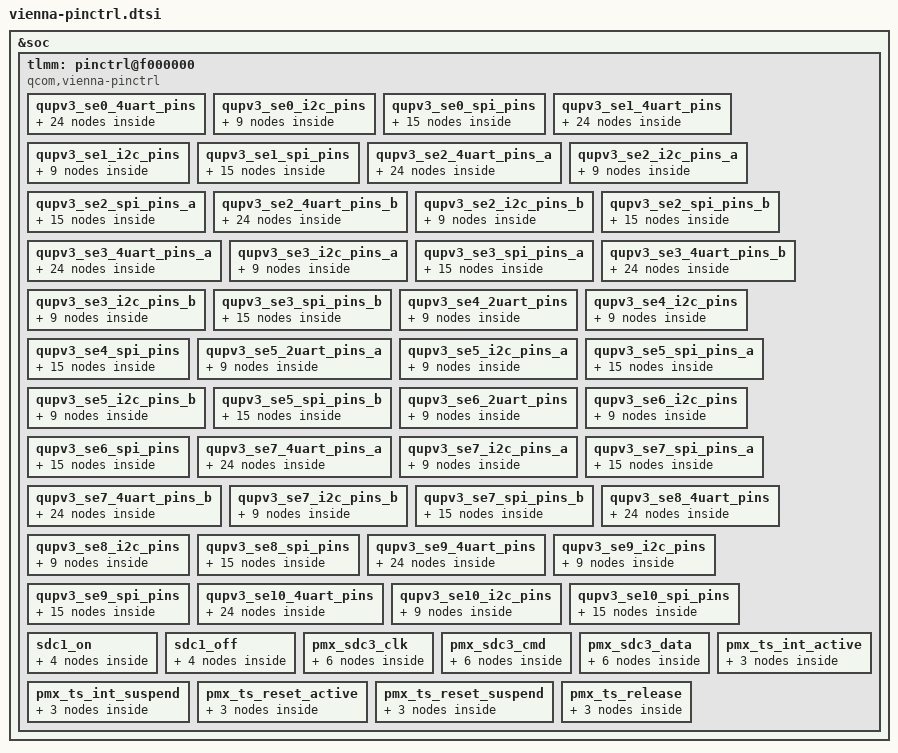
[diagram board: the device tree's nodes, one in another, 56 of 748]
// SPDX-License-Identifier: BSD-3-Clause
/*
 *Copyright (c) Qualcomm Technologies, Inc. and/or its subsidiaries.
 */

&soc {

	tlmm: pinctrl@f000000 {
		compatible = "qcom,vienna-pinctrl";
		reg = <0x0F000000 0x1000000>;
		interrupts = <GIC_SPI 208 IRQ_TYPE_LEVEL_HIGH>;
		gpio-controller;
		#gpio-cells = <2>;
		interrupt-controller;
		#interrupt-cells = <2>;
		wakeup-parent = <&pdc>;
		qcom,gpios-reserved = <0 1 2 3 14 15 73 74 88>;

		qupv3_se0_4uart_pins: qupv3_se0_4uart_pins {
			qupv3_se0_default_cts: qupv3_se0_default_cts {
				mux {
					pins = "gpio0";
					function = "gpio";
				};

				config {
					pins = "gpio0";
					drive-strength = <2>;
					bias-disable;
				};
			};

			qupv3_se0_default_rts: qupv3_se0_default_rts {
				mux {
					pins = "gpio1";
					function = "gpio";
				};

				config {
					pins = "gpio1";
					drive-strength = <2>;
					bias-pull-down;
				};
			};

			qupv3_se0_default_tx: qupv3_se0_default_tx {
				mux {
					pins = "gpio2";
					function = "gpio";
				};

				config {
					pins = "gpio2";
					drive-strength = <2>;
					bias-pull-up;
				};
			};

			qupv3_se0_default_rx: qupv3_se0_default_rx {
				mux {
					pins = "gpio3";
					function = "gpio";
				};

				config {
					pins = "gpio3";
					drive-strength = <2>;
					bias-pull-down;
				};
			};

			qupv3_se0_cts: qupv3_se0_cts {
				mux {
					pins = "gpio0";
					function = "qup0_se0_l0";
				};

				config {
					pins = "gpio0";
					drive-strength = <2>;
					bias-disable;
				};
			};

			qupv3_se0_rts: qupv3_se0_rts {
				mux {
					pins = "gpio1";
					function = "qup0_se0_l1";
				};

				config {
					pins = "gpio1";
					drive-strength = <2>;
					bias-pull-down;
				};
			};

			qupv3_se0_tx: qupv3_se0_tx {
				mux {
					pins = "gpio2";
					function = "qup0_se0_l2";
				};

				config {
					pins = "gpio2";
					drive-strength = <2>;
					bias-pull-up;
				};
			};

			qupv3_se0_rx_active: qupv3_se0_rx_active {
				mux {
					pins = "gpio3";
					function = "qup0_se0_l3";
				};

				config {
					pins = "gpio3";
					drive-strength = <2>;
					bias-disable;
				};
			};
		};

		qupv3_se0_i2c_pins: qupv3_se0_i2c_pins {
			qupv3_se0_i2c_sda_active: qupv3_se0_i2c_sda_active {
				mux {
					pins = "gpio0";
					function = "qup0_se0_l0";
				};

				config {
					pins = "gpio0";
					drive-strength = <2>;
					bias-pull-up;
					qcom,i2c_pull;
				};
			};

			qupv3_se0_i2c_scl_active: qupv3_se0_i2c_scl_active {
				mux {
					pins = "gpio1";
					function = "qup0_se0_l1";
				};

				config {
					pins = "gpio1";
					drive-strength = <2>;
					bias-pull-up;
					qcom,i2c_pull;
				};
			};

			qupv3_se0_i2c_sleep: qupv3_se0_i2c_sleep {
				mux {
					pins = "gpio0", "gpio1";
					function = "gpio";
				};

				config {
					pins = "gpio0", "gpio1";
					drive-strength = <2>;
				};
			};
		};

		qupv3_se0_spi_pins: qupv3_se0_spi_pins {
			qupv3_se0_spi_miso_active: qupv3_se0_spi_miso_active {
				mux {
					pins = "gpio0";
					function = "qup0_se0_l0";
				};

				config {
					pins = "gpio0";
					drive-strength = <6>;
					bias-disable;
				};
			};

			qupv3_se0_spi_mosi_active: qupv3_se0_spi_mosi_active {
				mux {
					pins = "gpio1";
					function = "qup0_se0_l1";
				};

				config {
					pins = "gpio1";
					drive-strength = <6>;
					bias-disable;
				};
			};

			qupv3_se0_spi_clk_active: qupv3_se0_spi_clk_active {
				mux {
					pins = "gpio2";
					function = "qup0_se0_l2";
				};

				config {
					pins = "gpio2";
					drive-strength = <6>;
					bias-disable;
				};
			};

			qupv3_se0_spi_cs_active: qupv3_se0_spi_cs_active {
				mux {
					pins = "gpio3";
					function = "qup0_se0_l3";
				};

				config {
					pins = "gpio3";
					drive-strength = <6>;
					bias-disable;
				};
			};

			qupv3_se0_spi_sleep: qupv3_se0_spi_sleep {
				mux {
					pins = "gpio0", "gpio1",
						"gpio2", "gpio3";
					function = "gpio";
				};

				config {
					pins = "gpio0", "gpio1",
						"gpio2", "gpio3";
					drive-strength = <2>;
					bias-disable;
				};
			};
		};

		qupv3_se1_4uart_pins: qupv3_se1_4uart_pins {
			qupv3_se1_default_cts: qupv3_se1_default_cts {
				mux {
					pins = "gpio4";
					function = "gpio";
				};

				config {
					pins = "gpio4";
					drive-strength = <2>;
					bias-disable;
				};
			};

			qupv3_se1_default_rts: qupv3_se1_default_rts {
				mux {
					pins = "gpio5";
					function = "gpio";
				};

				config {
					pins = "gpio5";
					drive-strength = <2>;
					bias-pull-down;
				};
			};

			qupv3_se1_default_tx: qupv3_se1_default_tx {
				mux {
					pins = "gpio7";
					function = "gpio";
				};

				config {
					pins = "gpio7";
					drive-strength = <2>;
					bias-pull-up;
				};
			};

			qupv3_se1_default_rx: qupv3_se1_default_rx {
				mux {
					pins = "gpio24";
					function = "gpio";
				};

				config {
					pins = "gpio24";
					drive-strength = <2>;
					bias-pull-down;
				};
			};

			qupv3_se1_cts: qupv3_se1_cts {
				mux {
					pins = "gpio4";
					function = "qup0_se1_l0";
				};

				config {
					pins = "gpio4";
					drive-strength = <2>;
					bias-disable;
				};
			};

			qupv3_se1_rts: qupv3_se1_rts {
				mux {
					pins = "gpio5";
					function = "qup0_se1_l1";
				};

				config {
					pins = "gpio5";
					drive-strength = <2>;
					bias-pull-down;
				};
			};

			qupv3_se1_tx: qupv3_se1_tx {
				mux {
					pins = "gpio7";
					function = "qup0_se1_l2";
				};

				config {
					pins = "gpio7";
					drive-strength = <2>;
					bias-pull-up;
				};
			};

			qupv3_se1_rx_active: qupv3_se1_rx_active {
				mux {
					pins = "gpio24";
					function = "qup0_se1_l3";
				};

				config {
					pins = "gpio24";
					drive-strength = <2>;
					bias-disable;
				};
			};
		};

		qupv3_se1_i2c_pins: qupv3_se1_i2c_pins {
			qupv3_se1_i2c_sda_active: qupv3_se1_i2c_sda_active {
				mux {
					pins = "gpio4";
					function = "qup0_se1_l0";
				};

				config {
					pins = "gpio4";
					drive-strength = <2>;
					bias-pull-up;
					qcom,i2c_pull;
				};
			};

			qupv3_se1_i2c_scl_active: qupv3_se1_i2c_scl_active {
				mux {
					pins = "gpio5";
					function = "qup0_se1_l1";
				};

				config {
					pins = "gpio5";
					drive-strength = <2>;
					bias-pull-up;
					qcom,i2c_pull;
				};
			};

			qupv3_se1_i2c_sleep: qupv3_se1_i2c_sleep {
				mux {
					pins = "gpio4", "gpio5";
					function = "gpio";
				};

				config {
					pins = "gpio4", "gpio5";
					drive-strength = <2>;
				};
			};
		};

		qupv3_se1_spi_pins: qupv3_se1_spi_pins {
			qupv3_se1_spi_miso_active: qupv3_se1_spi_miso_active {
				mux {
					pins = "gpio4";
					function = "qup0_se1_l0";
				};

				config {
					pins = "gpio4";
					drive-strength = <6>;
					bias-disable;
				};
			};

			qupv3_se1_spi_mosi_active: qupv3_se1_spi_mosi_active {
				mux {
					pins = "gpio5";
					function = "qup0_se1_l1";
				};

				config {
					pins = "gpio5";
					drive-strength = <6>;
					bias-disable;
				};
			};

			qupv3_se1_spi_clk_active: qupv3_se1_spi_clk_active {
				mux {
					pins = "gpio7";
					function = "qup0_se1_l2";
				};

				config {
					pins = "gpio7";
					drive-strength = <6>;
					bias-disable;
				};
			};

			qupv3_se1_spi_cs_active: qupv3_se1_spi_cs_active {
				mux {
					pins = "gpio24";
					function = "qup0_se1_l3";
				};

				config {
					pins = "gpio24";
					drive-strength = <6>;
					bias-disable;
				};
			};

			qupv3_se1_spi_sleep: qupv3_se1_spi_sleep {
				mux {
					pins = "gpio4", "gpio5",
						"gpio7", "gpio24";
					function = "gpio";
				};

				config {
					pins = "gpio4", "gpio5",
						"gpio7", "gpio24";
					drive-strength = <2>;
					bias-disable;
				};
			};
		};

		qupv3_se2_4uart_pins_a: qupv3_se2_4uart_pins_a {
			qupv3_se2_default_cts_a: qupv3_se2_default_cts_a {
				mux {
					pins = "gpio8";
					function = "gpio";
				};

				config {
					pins = "gpio8";
					drive-strength = <2>;
					bias-disable;
				};
			};

			qupv3_se2_default_rts_a: qupv3_se2_default_rts_a {
				mux {
					pins = "gpio9";
					function = "gpio";
				};

				config {
					pins = "gpio9";
					drive-strength = <2>;
					bias-pull-down;
				};
			};

			qupv3_se2_default_tx_a: qupv3_se2_default_tx_a {
				mux {
					pins = "gpio10";
					function = "gpio";
				};

				config {
					pins = "gpio10";
					drive-strength = <2>;
					bias-pull-up;
				};
			};

			qupv3_se2_default_rx_a: qupv3_se2_default_rx_a {
				mux {
					pins = "gpio11";
					function = "gpio";
				};

				config {
					pins = "gpio11";
					drive-strength = <2>;
					bias-pull-down;
				};
			};

			qupv3_se2_cts_a: qupv3_se2_cts_a {
				mux {
					pins = "gpio8";
					function = "qup0_se2_l0_mira";
				};

				config {
					pins = "gpio8";
					drive-strength = <2>;
					bias-disable;
				};
			};

			qupv3_se2_rts_a: qupv3_se2_rts_a {
				mux {
					pins = "gpio9";
					function = "qup0_se2_l1_mira";
				};

				config {
					pins = "gpio9";
					drive-strength = <2>;
					bias-pull-down;
				};
			};

			qupv3_se2_tx_a: qupv3_se2_tx_a {
				mux {
					pins = "gpio10";
					function = "qup0_se2_l2_mira";
				};

				config {
					pins = "gpio10";
					drive-strength = <2>;
					bias-pull-up;
				};
			};

			qupv3_se2_rx_active_a: qupv3_se2_rx_active_a {
				mux {
					pins = "gpio11";
					function = "qup0_se2_l3_mira";
				};

				config {
					pins = "gpio11";
					drive-strength = <2>;
					bias-disable;
				};
			};
		};

		qupv3_se2_i2c_pins_a: qupv3_se2_i2c_pins_a {
			qupv3_se2_i2c_sda_active_a: qupv3_se2_i2c_sda_active_a {
				mux {
					pins = "gpio8";
					function = "qup0_se2_l0_mira";
				};

				config {
					pins = "gpio8";
					drive-strength = <2>;
					bias-pull-up;
					qcom,i2c_pull;
				};
			};

			qupv3_se2_i2c_scl_active_a: qupv3_se2_i2c_scl_active_a {
				mux {
					pins = "gpio9";
					function = "qup0_se2_l1_mira";
				};

				config {
					pins = "gpio9";
					drive-strength = <2>;
					bias-pull-up;
					qcom,i2c_pull;
				};
			};

			qupv3_se2_i2c_sleep_a: qupv3_se2_i2c_sleep_a {
				mux {
					pins = "gpio8", "gpio9";
					function = "gpio";
				};

				config {
					pins = "gpio8", "gpio9";
					drive-strength = <2>;
				};
			};
		};

		qupv3_se2_spi_pins_a: qupv3_se2_spi_pins_a {
			qupv3_se2_spi_miso_active_a: qupv3_se2_spi_miso_active_a {
				mux {
					pins = "gpio8";
					function = "qup0_se2_l0_mira";
				};

				config {
					pins = "gpio8";
					drive-strength = <6>;
					bias-disable;
				};
			};

			qupv3_se2_spi_mosi_active_a: qupv3_se2_spi_mosi_active_a {
				mux {
					pins = "gpio9";
					function = "qup0_se2_l1_mira";
				};

				config {
					pins = "gpio9";
					drive-strength = <6>;
					bias-disable;
				};
			};

			qupv3_se2_spi_clk_active_a: qupv3_se2_spi_clk_active_a {
				mux {
					pins = "gpio10";
					function = "qup0_se2_l2_mira";
				};

				config {
					pins = "gpio10";
					drive-strength = <6>;
					bias-disable;
				};
			};

			qupv3_se2_spi_cs_active_a: qupv3_se2_spi_cs_active_a {
				mux {
					pins = "gpio11";
					function = "qup0_se2_l3_mira";
				};

				config {
					pins = "gpio11";
					drive-strength = <6>;
					bias-disable;
				};
			};

			qupv3_se2_spi_sleep_a: qupv3_se2_spi_sleep_a {
				mux {
					pins = "gpio8", "gpio9",
						"gpio10", "gpio11";
					function = "gpio";
				};

				config {
					pins = "gpio8", "gpio9",
						"gpio10", "gpio11";
					drive-strength = <2>;
					bias-disable;
				};
			};
		};

		qupv3_se2_4uart_pins_b: qupv3_se2_4uart_pins_b {
			qupv3_se2_default_cts_b: qupv3_se2_default_cts_b {
				mux {
					pins = "gpio134";
					function = "gpio";
				};

				config {
					pins = "gpio134";
					drive-strength = <2>;
					bias-disable;
				};
			};

			qupv3_se2_default_rts_b: qupv3_se2_default_rts_b {
				mux {
					pins = "gpio133";
					function = "gpio";
				};

				config {
					pins = "gpio133";
					drive-strength = <2>;
					bias-pull-down;
				};
			};

			qupv3_se2_default_tx_b: qupv3_se2_default_tx_b {
				mux {
					pins = "gpio132";
					function = "gpio";
				};

				config {
					pins = "gpio132";
					drive-strength = <2>;
					bias-pull-up;
				};
			};

			qupv3_se2_default_rx_b: qupv3_se2_default_rx_b {
				mux {
					pins = "gpio131";
					function = "gpio";
				};

				config {
					pins = "gpio131";
					drive-strength = <2>;
					bias-pull-down;
				};
			};

			qupv3_se2_cts_b: qupv3_se2_cts_b {
				mux {
					pins = "gpio134";
					function = "qup0_se2_l0_mirb";
				};

				config {
					pins = "gpio134";
					drive-strength = <2>;
					bias-disable;
				};
			};

			qupv3_se2_rts_b: qupv3_se2_rts_b {
				mux {
					pins = "gpio133";
					function = "qup0_se2_l1_mirb";
				};

				config {
					pins = "gpio133";
					drive-strength = <2>;
					bias-pull-down;
				};
			};

			qupv3_se2_tx_b: qupv3_se2_tx_b {
				mux {
					pins = "gpio132";
					function = "qup0_se2_l2_mirb";
				};

				config {
					pins = "gpio132";
					drive-strength = <2>;
					bias-pull-up;
				};
			};

			qupv3_se2_rx_active_b: qupv3_se2_rx_active_b {
				mux {
					pins = "gpio131";
					function = "qup0_se2_l3_mirb";
				};

				config {
					pins = "gpio131";
					drive-strength = <2>;
					bias-disable;
				};
			};
		};

		qupv3_se2_i2c_pins_b: qupv3_se2_i2c_pins_b {
			qupv3_se2_i2c_sda_active_b: qupv3_se2_i2c_sda_active_b {
				mux {
					pins = "gpio134";
					function = "qup0_se2_l0_mirb";
				};

				config {
					pins = "gpio134";
					drive-strength = <2>;
					bias-pull-up;
					qcom,i2c_pull;
				};
			};

			qupv3_se2_i2c_scl_active_b: qupv3_se2_i2c_scl_active_b {
				mux {
					pins = "gpio133";
					function = "qup0_se2_l1_mirb";
				};

				config {
					pins = "gpio133";
					drive-strength = <2>;
					bias-pull-up;
					qcom,i2c_pull;
				};
			};

			qupv3_se2_i2c_sleep_b: qupv3_se2_i2c_sleep_b {
				mux {
					pins = "gpio134", "gpio133";
					function = "gpio";
				};

				config {
					pins = "gpio134", "gpio133";
					drive-strength = <2>;
				};
			};
		};

		qupv3_se2_spi_pins_b: qupv3_se2_spi_pins_b {
			qupv3_se2_spi_miso_active_b: qupv3_se2_spi_miso_active_b {
				mux {
					pins = "gpio134";
					function = "qup0_se2_l0_mirb";
				};

				config {
					pins = "gpio134";
					drive-strength = <6>;
					bias-disable;
				};
			};

			qupv3_se2_spi_mosi_active_b: qupv3_se2_spi_mosi_active_b {
				mux {
					pins = "gpio133";
					function = "qup0_se2_l1_mirb";
				};

				config {
					pins = "gpio133";
					drive-strength = <6>;
					bias-disable;
				};
			};

			qupv3_se2_spi_clk_active_b: qupv3_se2_spi_clk_active_b {
				mux {
					pins = "gpio132";
					function = "qup0_se2_l2_mirb";
				};

				config {
					pins = "gpio132";
					drive-strength = <6>;
					bias-disable;
				};
			};

			qupv3_se2_spi_cs_active_b: qupv3_se2_spi_cs_active_b {
				mux {
					pins = "gpio131";
					function = "qup0_se2_l3_mirb";
				};

				config {
					pins = "gpio131";
					drive-strength = <6>;
					bias-disable;
				};
			};

			qupv3_se2_spi_sleep_b: qupv3_se2_spi_sleep_b {
				mux {
					pins = "gpio134", "gpio133",
						"gpio132", "gpio131";
					function = "gpio";
				};

				config {
					pins = "gpio134", "gpio133",
						"gpio132", "gpio131";
					drive-strength = <2>;
					bias-disable;
				};
			};
		};

		qupv3_se3_4uart_pins_a: qupv3_se3_4uart_pins_a {
			qupv3_se3_default_cts_a: qupv3_se3_default_cts_a {
				mux {
					pins = "gpio8";
					function = "gpio";
				};

				config {
					pins = "gpio8";
					drive-strength = <2>;
					bias-disable;
				};
			};

			qupv3_se3_default_rts_a: qupv3_se3_default_rts_a {
				mux {
					pins = "gpio9";
					function = "gpio";
				};

				config {
					pins = "gpio9";
					drive-strength = <2>;
					bias-pull-down;
				};
			};

			qupv3_se3_default_tx_a: qupv3_se3_default_tx_a {
				mux {
					pins = "gpio10";
					function = "gpio";
				};

				config {
					pins = "gpio10";
					drive-strength = <2>;
					bias-pull-up;
				};
			};

			qupv3_se3_default_rx_a: qupv3_se3_default_rx_a {
				mux {
					pins = "gpio11";
					function = "gpio";
				};

				config {
					pins = "gpio11";
					drive-strength = <2>;
					bias-pull-down;
				};
			};

			qupv3_se3_cts_a: qupv3_se3_cts_a {
				mux {
					pins = "gpio8";
					function = "qup0_se3_l0_mirb";
				};

				config {
					pins = "gpio8";
					drive-strength = <2>;
					bias-disable;
				};
			};

			qupv3_se3_rts_a: qupv3_se3_rts_a {
				mux {
					pins = "gpio9";
					function = "qup0_se3_l1_mirb";
				};

				config {
					pins = "gpio9";
					drive-strength = <2>;
					bias-pull-down;
				};
			};

			qupv3_se3_tx_a: qupv3_se3_tx_a {
				mux {
					pins = "gpio10";
					function = "qup0_se3_l2_mirb";
				};

				config {
					pins = "gpio10";
					drive-strength = <2>;
					bias-pull-up;
				};
			};

			qupv3_se3_rx_active_a: qupv3_se3_rx_active_a {
				mux {
					pins = "gpio11";
					function = "qup0_se3_l3_mirb";
				};

				config {
					pins = "gpio11";
					drive-strength = <2>;
					bias-disable;
				};
			};
		};

		qupv3_se3_i2c_pins_a: qupv3_se3_i2c_pins_a {
			qupv3_se3_i2c_sda_active_a: qupv3_se3_i2c_sda_active_a {
				mux {
					pins = "gpio8";
					function = "qup0_se3_l0_mirb";
				};

				config {
					pins = "gpio8";
					drive-strength = <2>;
					bias-pull-up;
					qcom,i2c_pull;
				};
			};

			qupv3_se3_i2c_scl_active_a: qupv3_se3_i2c_scl_active_a {
				mux {
					pins = "gpio9";
					function = "qup0_se3_l1_mirb";
				};

				config {
					pins = "gpio9";
					drive-strength = <2>;
					bias-pull-up;
					qcom,i2c_pull;
				};
			};

			qupv3_se3_i2c_sleep_a: qupv3_se3_i2c_sleep_a {
				mux {
					pins = "gpio8", "gpio9";
					function = "gpio";
				};

				config {
					pins = "gpio8", "gpio9";
					drive-strength = <2>;
				};
			};
		};

		qupv3_se3_spi_pins_a: qupv3_se3_spi_pins_a {
			qupv3_se3_spi_miso_active_a: qupv3_se3_spi_miso_active_a {
				mux {
					pins = "gpio8";
					function = "qup0_se3_l0_mirb";
				};

				config {
					pins = "gpio8";
					drive-strength = <6>;
					bias-disable;
				};
			};

			qupv3_se3_spi_mosi_active_a: qupv3_se3_spi_mosi_active_a {
				mux {
					pins = "gpio9";
					function = "qup0_se3_l1_mirb";
				};

				config {
					pins = "gpio9";
					drive-strength = <6>;
					bias-disable;
				};
			};

			qupv3_se3_spi_clk_active_a: qupv3_se3_spi_clk_active_a {
				mux {
					pins = "gpio10";
					function = "qup0_se3_l2_mirb";
				};

				config {
					pins = "gpio10";
					drive-strength = <6>;
					bias-disable;
				};
			};

			qupv3_se3_spi_cs_active_a: qupv3_se3_spi_cs_active_a {
				mux {
					pins = "gpio11";
					function = "qup0_se3_l3_mirb";
				};

				config {
					pins = "gpio11";
					drive-strength = <6>;
					bias-disable;
				};
			};

			qupv3_se3_spi_sleep_a: qupv3_se3_spi_sleep_a {
				mux {
					pins = "gpio8", "gpio9",
						"gpio10", "gpio11";
					function = "gpio";
				};

				config {
					pins = "gpio8", "gpio9",
						"gpio10", "gpio11";
					drive-strength = <2>;
					bias-disable;
				};
			};
		};

		qupv3_se3_4uart_pins_b: qupv3_se3_4uart_pins_b {
			qupv3_se3_default_cts_b: qupv3_se3_default_cts_b {
				mux {
					pins = "gpio111";
					function = "gpio";
				};

				config {
					pins = "gpio111";
					drive-strength = <2>;
					bias-disable;
				};
			};

			qupv3_se3_default_rts_b: qupv3_se3_default_rts_b {
				mux {
					pins = "gpio112";
					function = "gpio";
				};

				config {
					pins = "gpio112";
					drive-strength = <2>;
					bias-pull-down;
				};
			};

			qupv3_se3_default_tx_b: qupv3_se3_default_tx_b {
				mux {
					pins = "gpio14";
					function = "gpio";
				};

				config {
					pins = "gpio14";
					drive-strength = <2>;
					bias-pull-up;
				};
			};

			qupv3_se3_default_rx_b: qupv3_se3_default_rx_b {
				mux {
					pins = "gpio15";
					function = "gpio";
				};

				config {
					pins = "gpio15";
					drive-strength = <2>;
					bias-pull-down;
				};
			};

			qupv3_se3_cts_b: qupv3_se3_cts_b {
				mux {
					pins = "gpio111";
					function = "qup0_se3_l0_mira";
				};

				config {
					pins = "gpio111";
					drive-strength = <2>;
					bias-disable;
				};
			};

			qupv3_se3_rts_b: qupv3_se3_rts_b {
				mux {
					pins = "gpio112";
					function = "qup0_se3_l1_mira";
				};

				config {
					pins = "gpio112";
					drive-strength = <2>;
					bias-pull-down;
				};
			};

			qupv3_se3_tx_b: qupv3_se3_tx_b {
				mux {
					pins = "gpio14";
					function = "qup0_se3_l2_mira";
				};

				config {
					pins = "gpio14";
					drive-strength = <2>;
					bias-pull-up;
				};
			};

			qupv3_se3_rx_active_b: qupv3_se3_rx_active_b {
				mux {
					pins = "gpio15";
					function = "qup0_se3_l3_mira";
				};

				config {
					pins = "gpio15";
					drive-strength = <2>;
					bias-disable;
				};
			};
		};

		qupv3_se3_i2c_pins_b: qupv3_se3_i2c_pins_b {
			qupv3_se3_i2c_sda_active_b: qupv3_se3_i2c_sda_active_b {
				mux {
					pins = "gpio111";
					function = "qup0_se3_l0_mira";
				};

				config {
					pins = "gpio111";
					drive-strength = <2>;
					bias-pull-up;
					qcom,i2c_pull;
				};
			};

			qupv3_se3_i2c_scl_active_b: qupv3_se3_i2c_scl_active_b {
				mux {
					pins = "gpio112";
					function = "qup0_se3_l1_mira";
				};

				config {
					pins = "gpio112";
					drive-strength = <2>;
					bias-pull-up;
					qcom,i2c_pull;
				};
			};

			qupv3_se3_i2c_sleep_b: qupv3_se3_i2c_sleep_b {
				mux {
					pins = "gpio111", "gpio112";
					function = "gpio";
				};

				config {
					pins = "gpio111", "gpio112";
					drive-strength = <2>;
				};
			};
		};

		qupv3_se3_spi_pins_b: qupv3_se3_spi_pins_b {
			qupv3_se3_spi_miso_active_b: qupv3_se3_spi_miso_active_b {
				mux {
					pins = "gpio111";
					function = "qup0_se3_l0_mira";
				};

				config {
					pins = "gpio111";
					drive-strength = <6>;
					bias-disable;
				};
			};

			qupv3_se3_spi_mosi_active_b: qupv3_se3_spi_mosi_active_b {
				mux {
					pins = "gpio112";
					function = "qup0_se3_l1_mira";
				};

				config {
					pins = "gpio112";
					drive-strength = <6>;
					bias-disable;
				};
			};

			qupv3_se3_spi_clk_active_b: qupv3_se3_spi_clk_active_b {
				mux {
					pins = "gpio14";
					function = "qup0_se3_l2_mira";
				};

				config {
					pins = "gpio14";
					drive-strength = <6>;
					bias-disable;
				};
			};

			qupv3_se3_spi_cs_active_b: qupv3_se3_spi_cs_active_b {
				mux {
					pins = "gpio15";
					function = "qup0_se3_l3_mira";
				};

				config {
					pins = "gpio15";
					drive-strength = <6>;
					bias-disable;
				};
			};

			qupv3_se3_spi_sleep_b: qupv3_se3_spi_sleep_b {
				mux {
					pins = "gpio111", "gpio112",
						"gpio14", "gpio15";
					function = "gpio";
				};

				config {
					pins = "gpio111", "gpio112",
						"gpio14", "gpio15";
					drive-strength = <2>;
					bias-disable;
				};
			};
		};

		qupv3_se4_2uart_pins: qupv3_se4_2uart_pins {
			qupv3_se4_2uart_tx_active: qupv3_se4_2uart_tx_active {
				mux {
					pins = "gpio18";
					function = "qup0_se4_l2";
				};

				config {
					pins = "gpio18";
					drive-strength = <2>;
					bias-disable;
				};
			};

			qupv3_se4_2uart_rx_active: qupv3_se4_2uart_rx_active {
				mux {
					pins = "gpio19";
					function = "qup0_se4_l3";
				};

				config {
					pins = "gpio19";
					drive-strength = <2>;
					bias-disable;
				};
			};

			qupv3_se4_2uart_sleep: qupv3_se4_2uart_sleep {
				mux {
					pins = "gpio18", "gpio19";
					function = "gpio";
				};

				config {
					pins = "gpio18", "gpio19";
					drive-strength = <2>;
					bias-pull-down;
				};
			};
		};

		qupv3_se4_i2c_pins: qupv3_se4_i2c_pins {
			qupv3_se4_i2c_sda_active: qupv3_se4_i2c_sda_active {
				mux {
					pins = "gpio16";
					function = "qup0_se4_l0";
				};

				config {
					pins = "gpio16";
					drive-strength = <2>;
					bias-pull-up;
					qcom,i2c_pull;
				};
			};

			qupv3_se4_i2c_scl_active: qupv3_se4_i2c_scl_active {
				mux {
					pins = "gpio17";
					function = "qup0_se4_l1";
				};

				config {
					pins = "gpio17";
					drive-strength = <2>;
					bias-pull-up;
					qcom,i2c_pull;
				};
			};

			qupv3_se4_i2c_sleep: qupv3_se4_i2c_sleep {
				mux {
					pins = "gpio16", "gpio17";
					function = "gpio";
				};

				config {
					pins = "gpio16", "gpio17";
					drive-strength = <2>;
				};
			};
		};

		qupv3_se4_spi_pins: qupv3_se4_spi_pins {
			qupv3_se4_spi_miso_active: qupv3_se4_spi_miso_active {
				mux {
					pins = "gpio16";
					function = "qup0_se4_l0";
				};

				config {
					pins = "gpio16";
					drive-strength = <6>;
					bias-disable;
				};
			};

			qupv3_se4_spi_mosi_active: qupv3_se4_spi_mosi_active {
				mux {
					pins = "gpio17";
					function = "qup0_se4_l1";
				};

				config {
					pins = "gpio17";
					drive-strength = <6>;
					bias-disable;
				};
			};

			qupv3_se4_spi_clk_active: qupv3_se4_spi_clk_active {
				mux {
					pins = "gpio18";
					function = "qup0_se4_l2";
				};

				config {
					pins = "gpio18";
					drive-strength = <6>;
					bias-disable;
				};
			};

			qupv3_se4_spi_cs_active: qupv3_se4_spi_cs_active {
				mux {
					pins = "gpio19";
					function = "qup0_se4_l3";
				};

				config {
					pins = "gpio19";
					drive-strength = <6>;
					bias-disable;
				};
			};

			qupv3_se4_spi_sleep: qupv3_se4_spi_sleep {
				mux {
					pins = "gpio16", "gpio17",
						"gpio18", "gpio19";
					function = "gpio";
				};

				config {
					pins = "gpio16", "gpio17",
						"gpio18", "gpio19";
					drive-strength = <2>;
					bias-disable;
				};
			};
		};

		qupv3_se5_2uart_pins_a: qupv3_se5_2uart_pins_a {
			qupv3_se5_2uart_tx_active_a: qupv3_se5_2uart_tx_active_a {
				mux {
					pins = "gpio21";
					function = "qup0_se5_l2_mira";
				};

				config {
					pins = "gpio21";
					drive-strength = <2>;
					bias-disable;
				};
			};

			qupv3_se5_2uart_rx_active_a: qupv3_se5_2uart_rx_active_a {
				mux {
					pins = "gpio20";
					function = "qup0_se5_l3_mira";
				};

				config {
					pins = "gpio20";
					drive-strength = <2>;
					bias-disable;
				};
			};

			qupv3_se5_2uart_sleep_a: qupv3_se5_2uart_sleep_a {
				mux {
					pins = "gpio21", "gpio20";
					function = "gpio";
				};

				config {
					pins = "gpio21", "gpio20";
					drive-strength = <2>;
					bias-pull-down;
				};
			};
		};

		qupv3_se5_i2c_pins_a: qupv3_se5_i2c_pins_a {
			qupv3_se5_i2c_sda_active_a: qupv3_se5_i2c_sda_active_a {
				mux {
					pins = "gpio23";
					function = "qup0_se5_l0_mira";
				};

				config {
					pins = "gpio23";
					drive-strength = <2>;
					bias-pull-up;
					qcom,i2c_pull;
				};
			};

			qupv3_se5_i2c_scl_active_a: qupv3_se5_i2c_scl_active_a {
				mux {
					pins = "gpio22";
					function = "qup0_se5_l1_mira";
				};

				config {
					pins = "gpio22";
					drive-strength = <2>;
					bias-pull-up;
					qcom,i2c_pull;
				};
			};

			qupv3_se5_i2c_sleep_a: qupv3_se5_i2c_sleep_a {
				mux {
					pins = "gpio23", "gpio22";
					function = "gpio";
				};

				config {
					pins = "gpio23", "gpio22";
					drive-strength = <2>;
				};
			};
		};

		qupv3_se5_spi_pins_a: qupv3_se5_spi_pins_a {
			qupv3_se5_spi_miso_active_a: qupv3_se5_spi_miso_active_a {
				mux {
					pins = "gpio23";
					function = "qup0_se5_l0_mira";
				};

				config {
					pins = "gpio23";
					drive-strength = <6>;
					bias-disable;
				};
			};

			qupv3_se5_spi_mosi_active_a: qupv3_se5_spi_mosi_active_a {
				mux {
					pins = "gpio22";
					function = "qup0_se5_l1_mira";
				};

				config {
					pins = "gpio22";
					drive-strength = <6>;
					bias-disable;
				};
			};

			qupv3_se5_spi_clk_active_a: qupv3_se5_spi_clk_active_a {
				mux {
					pins = "gpio21";
					function = "qup0_se5_l2_mira";
				};

				config {
					pins = "gpio21";
					drive-strength = <6>;
					bias-disable;
				};
			};

			qupv3_se5_spi_cs_active_a: qupv3_se5_spi_cs_active_a {
				mux {
					pins = "gpio20";
					function = "qup0_se5_l3_mira";
				};

				config {
					pins = "gpio20";
					drive-strength = <6>;
					bias-disable;
				};
			};

			qupv3_se5_spi_sleep_a: qupv3_se5_spi_sleep_a {
				mux {
					pins = "gpio23", "gpio22",
						"gpio21", "gpio20";
					function = "gpio";
				};

				config {
					pins = "gpio23", "gpio22",
						"gpio21", "gpio20";
					drive-strength = <2>;
					bias-disable;
				};
			};
		};

		qupv3_se5_i2c_pins_b: qupv3_se5_i2c_pins_b {
			qupv3_se5_i2c_sda_active_b: qupv3_se5_i2c_sda_active_b {
				mux {
					pins = "gpio33";
					function = "qup0_se5_l0_mirb";
				};

				config {
					pins = "gpio33";
					drive-strength = <2>;
					bias-pull-up;
					qcom,i2c_pull;
				};
			};

			qupv3_se5_i2c_scl_active_b: qupv3_se5_i2c_scl_active_b {
				mux {
					pins = "gpio35";
					function = "qup0_se5_l1_mirb";
				};

				config {
					pins = "gpio35";
					drive-strength = <2>;
					bias-pull-up;
					qcom,i2c_pull;
				};
			};

			qupv3_se5_i2c_sleep_b: qupv3_se5_i2c_sleep_b {
				mux {
					pins = "gpio33", "gpio35";
					function = "gpio";
				};

				config {
					pins = "gpio33", "gpio35";
					drive-strength = <2>;
				};
			};
		};

		qupv3_se5_spi_pins_b: qupv3_se5_spi_pins_b {
			qupv3_se5_spi_miso_active_b: qupv3_se5_spi_miso_active_b {
				mux {
					pins = "gpio33";
					function = "qup0_se5_l0_mirb";
				};

				config {
					pins = "gpio33";
					drive-strength = <6>;
					bias-disable;
				};
			};

			qupv3_se5_spi_mosi_active_b: qupv3_se5_spi_mosi_active_b {
				mux {
					pins = "gpio35";
					function = "qup0_se5_l1_mirb";
				};

				config {
					pins = "gpio35";
					drive-strength = <6>;
					bias-disable;
				};
			};

			qupv3_se5_spi_clk_active_b: qupv3_se5_spi_clk_active_b {
				mux {
					pins = "gpio39";
					function = "qup0_se5_l2_mirb";
				};

				config {
					pins = "gpio39";
					drive-strength = <6>;
					bias-disable;
				};
			};

			qupv3_se5_spi_cs_active_b: qupv3_se5_spi_cs_active_b {
				mux {
					pins = "gpio38";
					function = "qup0_se5_l3_mirb";
				};

				config {
					pins = "gpio38";
					drive-strength = <6>;
					bias-disable;
				};
			};

			qupv3_se5_spi_sleep_b: qupv3_se5_spi_sleep_b {
				mux {
					pins = "gpio33", "gpio35",
						"gpio39", "gpio38";
					function = "gpio";
				};

				config {
					pins = "gpio33", "gpio35",
						"gpio39", "gpio38";
					drive-strength = <2>;
					bias-disable;
				};
			};
		};

		qupv3_se6_2uart_pins: qupv3_se6_2uart_pins {
			qupv3_se6_2uart_tx_active: qupv3_se6_2uart_tx_active {
				mux {
					pins = "gpio117";
					function = "qup0_se6_l2";
				};

				config {
					pins = "gpio117";
					drive-strength = <2>;
					bias-disable;
				};
			};

			qupv3_se6_2uart_rx_active: qupv3_se6_2uart_rx_active {
				mux {
					pins = "gpio118";
					function = "qup0_se6_l3";
				};

				config {
					pins = "gpio118";
					drive-strength = <2>;
					bias-disable;
				};
			};

			qupv3_se6_2uart_sleep: qupv3_se6_2uart_sleep {
				mux {
					pins = "gpio117", "gpio118";
					function = "gpio";
				};

				config {
					pins = "gpio117", "gpio118";
					drive-strength = <2>;
					bias-pull-down;
				};
			};
		};

		qupv3_se6_i2c_pins: qupv3_se6_i2c_pins {
			qupv3_se6_i2c_sda_active: qupv3_se6_i2c_sda_active {
				mux {
					pins = "gpio28";
					function = "qup0_se6_l0";
				};

				config {
					pins = "gpio28";
					drive-strength = <2>;
					bias-pull-up;
					qcom,i2c_pull;
				};
			};

			qupv3_se6_i2c_scl_active: qupv3_se6_i2c_scl_active {
				mux {
					pins = "gpio29";
					function = "qup0_se6_l1";
				};

				config {
					pins = "gpio29";
					drive-strength = <2>;
					bias-pull-up;
					qcom,i2c_pull;
				};
			};

			qupv3_se6_i2c_sleep: qupv3_se6_i2c_sleep {
				mux {
					pins = "gpio28", "gpio29";
					function = "gpio";
				};

				config {
					pins = "gpio28", "gpio29";
					drive-strength = <2>;
				};
			};
		};

		qupv3_se6_spi_pins: qupv3_se6_spi_pins {
			qupv3_se6_spi_miso_active: qupv3_se6_spi_miso_active {
				mux {
					pins = "gpio28";
					function = "qup0_se6_l0";
				};

				config {
					pins = "gpio28";
					drive-strength = <6>;
					bias-disable;
				};
			};

			qupv3_se6_spi_mosi_active: qupv3_se6_spi_mosi_active {
				mux {
					pins = "gpio29";
					function = "qup0_se6_l1";
				};

				config {
					pins = "gpio29";
					drive-strength = <6>;
					bias-disable;
				};
			};

			qupv3_se6_spi_clk_active: qupv3_se6_spi_clk_active {
				mux {
					pins = "gpio117";
					function = "qup0_se6_l2";
				};

				config {
					pins = "gpio117";
					drive-strength = <6>;
					bias-disable;
				};
			};

			qupv3_se6_spi_cs_active: qupv3_se6_spi_cs_active {
				mux {
					pins = "gpio118";
					function = "qup0_se6_l3";
				};

				config {
					pins = "gpio118";
					drive-strength = <6>;
					bias-disable;
				};
			};

			qupv3_se6_spi_sleep: qupv3_se6_spi_sleep {
				mux {
					pins = "gpio28", "gpio29",
						"gpio117", "gpio118";
					function = "gpio";
				};

				config {
					pins = "gpio28", "gpio29",
						"gpio117", "gpio118";
					drive-strength = <2>;
					bias-disable;
				};
			};
		};

		qupv3_se7_4uart_pins_a: qupv3_se7_4uart_pins_a {
			qupv3_se7_default_cts_a: qupv3_se7_default_cts_a {
				mux {
					pins = "gpio23";
					function = "gpio";
				};

				config {
					pins = "gpio23";
					drive-strength = <2>;
					bias-disable;
				};
			};

			qupv3_se7_default_rts_a: qupv3_se7_default_rts_a {
				mux {
					pins = "gpio22";
					function = "gpio";
				};

				config {
					pins = "gpio22";
					drive-strength = <2>;
					bias-pull-down;
				};
			};

			qupv3_se7_default_tx_a: qupv3_se7_default_tx_a {
				mux {
					pins = "gpio21";
					function = "gpio";
				};

				config {
					pins = "gpio21";
					drive-strength = <2>;
					bias-pull-up;
				};
			};

			qupv3_se7_default_rx_a: qupv3_se7_default_rx_a {
				mux {
					pins = "gpio20";
					function = "gpio";
				};

				config {
					pins = "gpio20";
					drive-strength = <2>;
					bias-pull-down;
				};
			};

			qupv3_se7_cts_a: qupv3_se7_cts_a {
				mux {
					pins = "gpio23";
					function = "qup0_se7_l0_mira";
				};

				config {
					pins = "gpio23";
					drive-strength = <2>;
					bias-disable;
				};
			};

			qupv3_se7_rts_a: qupv3_se7_rts_a {
				mux {
					pins = "gpio22";
					function = "qup0_se7_l1_mira";
				};

				config {
					pins = "gpio22";
					drive-strength = <2>;
					bias-pull-down;
				};
			};

			qupv3_se7_tx_a: qupv3_se7_tx_a {
				mux {
					pins = "gpio21";
					function = "qup0_se7_l2_mira";
				};

				config {
					pins = "gpio21";
					drive-strength = <2>;
					bias-pull-up;
				};
			};

			qupv3_se7_rx_active_a: qupv3_se7_rx_active_a {
				mux {
					pins = "gpio20";
					function = "qup0_se7_l3_mira";
				};

				config {
					pins = "gpio20";
					drive-strength = <2>;
					bias-disable;
				};
			};
		};

		qupv3_se7_i2c_pins_a: qupv3_se7_i2c_pins_a {
			qupv3_se7_i2c_sda_active_a: qupv3_se7_i2c_sda_active_a {
				mux {
					pins = "gpio23";
					function = "qup0_se7_l0_mira";
				};

				config {
					pins = "gpio23";
					drive-strength = <2>;
					bias-pull-up;
					qcom,i2c_pull;
				};
			};

			qupv3_se7_i2c_scl_active_a: qupv3_se7_i2c_scl_active_a {
				mux {
					pins = "gpio22";
					function = "qup0_se7_l1_mira";
				};

				config {
					pins = "gpio22";
					drive-strength = <2>;
					bias-pull-up;
					qcom,i2c_pull;
				};
			};

			qupv3_se7_i2c_sleep_a: qupv3_se7_i2c_sleep_a {
				mux {
					pins = "gpio23", "gpio22";
					function = "gpio";
				};

				config {
					pins = "gpio23", "gpio22";
					drive-strength = <2>;
				};
			};
		};

		qupv3_se7_spi_pins_a: qupv3_se7_spi_pins_a {
			qupv3_se7_spi_miso_active_a: qupv3_se7_spi_miso_active_a {
				mux {
					pins = "gpio23";
					function = "qup0_se7_l0_mira";
				};

				config {
					pins = "gpio23";
					drive-strength = <6>;
					bias-disable;
				};
			};

			qupv3_se7_spi_mosi_active_a: qupv3_se7_spi_mosi_active_a {
				mux {
					pins = "gpio22";
					function = "qup0_se7_l1_mira";
				};

				config {
					pins = "gpio22";
					drive-strength = <6>;
					bias-disable;
				};
			};

			qupv3_se7_spi_clk_active_a: qupv3_se7_spi_clk_active_a {
				mux {
					pins = "gpio21";
					function = "qup0_se7_l2_mira";
				};

				config {
					pins = "gpio21";
					drive-strength = <6>;
					bias-disable;
				};
			};

			qupv3_se7_spi_cs_active_a: qupv3_se7_spi_cs_active_a {
				mux {
					pins = "gpio20";
					function = "qup0_se7_l3_mira";
				};

				config {
					pins = "gpio20";
					drive-strength = <6>;
					bias-disable;
				};
			};

			qupv3_se7_spi_sleep_a: qupv3_se7_spi_sleep_a {
				mux {
					pins = "gpio23", "gpio22",
						"gpio21", "gpio20";
					function = "gpio";
				};

				config {
					pins = "gpio23", "gpio22",
						"gpio21", "gpio20";
					drive-strength = <2>;
					bias-disable;
				};
			};
		};

		qupv3_se7_4uart_pins_b: qupv3_se7_4uart_pins_b {
			qupv3_se7_default_cts_b: qupv3_se7_default_cts_b {
				mux {
					pins = "gpio127";
					function = "gpio";
				};

				config {
					pins = "gpio127";
					drive-strength = <2>;
					bias-disable;
				};
			};

			qupv3_se7_default_rts_b: qupv3_se7_default_rts_b {
				mux {
					pins = "gpio128";
					function = "gpio";
				};

				config {
					pins = "gpio128";
					drive-strength = <2>;
					bias-pull-down;
				};
			};

			qupv3_se7_default_tx_b: qupv3_se7_default_tx_b {
				mux {
					pins = "gpio129";
					function = "gpio";
				};

				config {
					pins = "gpio129";
					drive-strength = <2>;
					bias-pull-up;
				};
			};

			qupv3_se7_default_rx_b: qupv3_se7_default_rx_b {
				mux {
					pins = "gpio130";
					function = "gpio";
				};

				config {
					pins = "gpio130";
					drive-strength = <2>;
					bias-pull-down;
				};
			};

			qupv3_se7_cts_b: qupv3_se7_cts_b {
				mux {
					pins = "gpio127";
					function = "qup0_se7_l0_mirb";
				};

				config {
					pins = "gpio127";
					drive-strength = <2>;
					bias-disable;
				};
			};

			qupv3_se7_rts_b: qupv3_se7_rts_b {
				mux {
					pins = "gpio128";
					function = "qup0_se7_l1_mirb";
				};

				config {
					pins = "gpio128";
					drive-strength = <2>;
					bias-pull-down;
				};
			};

			qupv3_se7_tx_b: qupv3_se7_tx_b {
				mux {
					pins = "gpio129";
					function = "qup0_se7_l2_mirb";
				};

				config {
					pins = "gpio129";
					drive-strength = <2>;
					bias-pull-up;
				};
			};

			qupv3_se7_rx_active_b: qupv3_se7_rx_active_b {
				mux {
					pins = "gpio130";
					function = "qup0_se7_l3_mirb";
				};

				config {
					pins = "gpio130";
					drive-strength = <2>;
					bias-disable;
				};
			};
		};

		qupv3_se7_i2c_pins_b: qupv3_se7_i2c_pins_b {
			qupv3_se7_i2c_sda_active_b: qupv3_se7_i2c_sda_active_b {
				mux {
					pins = "gpio127";
					function = "qup0_se7_l0_mirb";
				};

				config {
					pins = "gpio127";
					drive-strength = <2>;
					bias-pull-up;
					qcom,i2c_pull;
				};
			};

			qupv3_se7_i2c_scl_active_b: qupv3_se7_i2c_scl_active_b {
				mux {
					pins = "gpio128";
					function = "qup0_se7_l1_mirb";
				};

				config {
					pins = "gpio128";
					drive-strength = <2>;
					bias-pull-up;
					qcom,i2c_pull;
				};
			};

			qupv3_se7_i2c_sleep_b: qupv3_se7_i2c_sleep_b {
				mux {
					pins = "gpio127", "gpio128";
					function = "gpio";
				};

				config {
					pins = "gpio127", "gpio128";
					drive-strength = <2>;
				};
			};
		};

		qupv3_se7_spi_pins_b: qupv3_se7_spi_pins_b {
			qupv3_se7_spi_miso_active_b: qupv3_se7_spi_miso_active_b {
				mux {
					pins = "gpio127";
					function = "qup0_se7_l0_mirb";
				};

				config {
					pins = "gpio127";
					drive-strength = <6>;
					bias-disable;
				};
			};

			qupv3_se7_spi_mosi_active_b: qupv3_se7_spi_mosi_active_b {
				mux {
					pins = "gpio128";
					function = "qup0_se7_l1_mirb";
				};

				config {
					pins = "gpio128";
					drive-strength = <6>;
					bias-disable;
				};
			};

			qupv3_se7_spi_clk_active_b: qupv3_se7_spi_clk_active_b {
				mux {
					pins = "gpio129";
					function = "qup0_se7_l2_mirb";
				};

				config {
					pins = "gpio129";
					drive-strength = <6>;
					bias-disable;
				};
			};

			qupv3_se7_spi_cs_active_b: qupv3_se7_spi_cs_active_b {
				mux {
					pins = "gpio130";
					function = "qup0_se7_l3_mirb";
				};

				config {
					pins = "gpio130";
					drive-strength = <6>;
					bias-disable;
				};
			};

			qupv3_se7_spi_sleep_b: qupv3_se7_spi_sleep_b {
				mux {
					pins = "gpio127", "gpio128",
						"gpio129", "gpio130";
					function = "gpio";
				};

				config {
					pins = "gpio127", "gpio128",
						"gpio129", "gpio130";
					drive-strength = <2>;
					bias-disable;
				};
			};
		};

		qupv3_se8_4uart_pins: qupv3_se8_4uart_pins {
			qupv3_se8_default_cts: qupv3_se8_default_cts {
				mux {
					pins = "gpio72";
					function = "gpio";
				};

				config {
					pins = "gpio72";
					drive-strength = <2>;
					bias-disable;
				};
			};

			qupv3_se8_default_rts: qupv3_se8_default_rts {
				mux {
					pins = "gpio40";
					function = "gpio";
				};

				config {
					pins = "gpio40";
					drive-strength = <2>;
					bias-pull-down;
				};
			};

			qupv3_se8_default_tx: qupv3_se8_default_tx {
				mux {
					pins = "gpio14";
					function = "gpio";
				};

				config {
					pins = "gpio14";
					drive-strength = <2>;
					bias-pull-up;
				};
			};

			qupv3_se8_default_rx: qupv3_se8_default_rx {
				mux {
					pins = "gpio15";
					function = "gpio";
				};

				config {
					pins = "gpio15";
					drive-strength = <2>;
					bias-pull-down;
				};
			};

			qupv3_se8_cts: qupv3_se8_cts {
				mux {
					pins = "gpio72";
					function = "qup0_se8_l0";
				};

				config {
					pins = "gpio72";
					drive-strength = <2>;
					bias-disable;
				};
			};

			qupv3_se8_rts: qupv3_se8_rts {
				mux {
					pins = "gpio40";
					function = "qup0_se8_l1";
				};

				config {
					pins = "gpio40";
					drive-strength = <2>;
					bias-pull-down;
				};
			};

			qupv3_se8_tx: qupv3_se8_tx {
				mux {
					pins = "gpio14";
					function = "qup0_se8_l2";
				};

				config {
					pins = "gpio14";
					drive-strength = <2>;
					bias-pull-up;
				};
			};

			qupv3_se8_rx_active: qupv3_se8_rx_active {
				mux {
					pins = "gpio15";
					function = "qup0_se8_l3";
				};

				config {
					pins = "gpio15";
					drive-strength = <2>;
					bias-disable;
				};
			};
		};

		qupv3_se8_i2c_pins: qupv3_se8_i2c_pins {
			qupv3_se8_i2c_sda_active: qupv3_se8_i2c_sda_active {
				mux {
					pins = "gpio72";
					function = "qup0_se8_l0";
				};

				config {
					pins = "gpio72";
					drive-strength = <2>;
					bias-pull-up;
					qcom,i2c_pull;
					qcom,apps;
				};
			};

			qupv3_se8_i2c_scl_active: qupv3_se8_i2c_scl_active {
				mux {
					pins = "gpio40";
					function = "qup0_se8_l1";
				};

				config {
					pins = "gpio40";
					drive-strength = <2>;
					bias-pull-up;
					qcom,i2c_pull;
					qcom,apps;
				};
			};

			qupv3_se8_i2c_sleep: qupv3_se8_i2c_sleep {
				mux {
					pins = "gpio72", "gpio40";
					function = "gpio";
				};

				config {
					pins = "gpio72", "gpio40";
					drive-strength = <2>;
					qcom,remote;
				};
			};
		};

		qupv3_se8_spi_pins: qupv3_se8_spi_pins {
			qupv3_se8_spi_miso_active: qupv3_se8_spi_miso_active {
				mux {
					pins = "gpio72";
					function = "qup0_se8_l0";
				};

				config {
					pins = "gpio72";
					drive-strength = <6>;
					bias-disable;
				};
			};

			qupv3_se8_spi_mosi_active: qupv3_se8_spi_mosi_active {
				mux {
					pins = "gpio40";
					function = "qup0_se8_l1";
				};

				config {
					pins = "gpio40";
					drive-strength = <6>;
					bias-disable;
				};
			};

			qupv3_se8_spi_clk_active: qupv3_se8_spi_clk_active {
				mux {
					pins = "gpio14";
					function = "qup0_se8_l2";
				};

				config {
					pins = "gpio14";
					drive-strength = <6>;
					bias-disable;
				};
			};

			qupv3_se8_spi_cs_active: qupv3_se8_spi_cs_active {
				mux {
					pins = "gpio15";
					function = "qup0_se8_l3";
				};

				config {
					pins = "gpio15";
					drive-strength = <6>;
					bias-disable;
				};
			};

			qupv3_se8_spi_sleep: qupv3_se8_spi_sleep {
				mux {
					pins = "gpio72", "gpio40",
						"gpio14", "gpio15";
					function = "gpio";
				};

				config {
					pins = "gpio72", "gpio40",
						"gpio14", "gpio15";
					drive-strength = <2>;
					bias-disable;
				};
			};
		};

		qupv3_se9_4uart_pins: qupv3_se9_4uart_pins {
			qupv3_se9_default_cts: qupv3_se9_default_cts {
				mux {
					pins = "gpio28";
					function = "gpio";
				};

				config {
					pins = "gpio28";
					drive-strength = <2>;
					bias-disable;
				};
			};

			qupv3_se9_default_rts: qupv3_se9_default_rts {
				mux {
					pins = "gpio29";
					function = "gpio";
				};

				config {
					pins = "gpio29";
					drive-strength = <2>;
					bias-pull-down;
				};
			};

			qupv3_se9_default_tx: qupv3_se9_default_tx {
				mux {
					pins = "gpio14";
					function = "gpio";
				};

				config {
					pins = "gpio14";
					drive-strength = <2>;
					bias-pull-up;
				};
			};

			qupv3_se9_default_rx: qupv3_se9_default_rx {
				mux {
					pins = "gpio15";
					function = "gpio";
				};

				config {
					pins = "gpio15";
					drive-strength = <2>;
					bias-pull-down;
				};
			};

			qupv3_se9_cts: qupv3_se9_cts {
				mux {
					pins = "gpio28";
					function = "qup0_se9_l0";
				};

				config {
					pins = "gpio28";
					drive-strength = <2>;
					bias-disable;
				};
			};

			qupv3_se9_rts: qupv3_se9_rts {
				mux {
					pins = "gpio29";
					function = "qup0_se9_l1";
				};

				config {
					pins = "gpio29";
					drive-strength = <2>;
					bias-pull-down;
				};
			};

			qupv3_se9_tx: qupv3_se9_tx {
				mux {
					pins = "gpio14";
					function = "qup0_se9_l2";
				};

				config {
					pins = "gpio14";
					drive-strength = <2>;
					bias-pull-up;
				};
			};

			qupv3_se9_rx_active: qupv3_se9_rx_active {
				mux {
					pins = "gpio15";
					function = "qup0_se9_l3";
				};

				config {
					pins = "gpio15";
					drive-strength = <2>;
					bias-disable;
				};
			};
		};

		qupv3_se9_i2c_pins: qupv3_se9_i2c_pins {
			qupv3_se9_i2c_sda_active: qupv3_se9_i2c_sda_active {
				mux {
					pins = "gpio28";
					function = "qup0_se9_l0";
				};

				config {
					pins = "gpio28";
					drive-strength = <2>;
					bias-pull-up;
					qcom,i2c_pull;
					qcom,apps;
				};
			};

			qupv3_se9_i2c_scl_active: qupv3_se9_i2c_scl_active {
				mux {
					pins = "gpio29";
					function = "qup0_se9_l1";
				};

				config {
					pins = "gpio29";
					drive-strength = <2>;
					bias-pull-up;
					qcom,i2c_pull;
					qcom,apps;
				};
			};

			qupv3_se9_i2c_sleep: qupv3_se9_i2c_sleep {
				mux {
					pins = "gpio28", "gpio29";
					function = "gpio";
				};

				config {
					pins = "gpio28", "gpio29";
					drive-strength = <2>;
					qcom,remote;
				};
			};
		};

		qupv3_se9_spi_pins: qupv3_se9_spi_pins {
			qupv3_se9_spi_miso_active: qupv3_se9_spi_miso_active {
				mux {
					pins = "gpio28";
					function = "qup0_se9_l0";
				};

				config {
					pins = "gpio28";
					drive-strength = <6>;
					bias-disable;
				};
			};

			qupv3_se9_spi_mosi_active: qupv3_se9_spi_mosi_active {
				mux {
					pins = "gpio29";
					function = "qup0_se9_l1";
				};

				config {
					pins = "gpio29";
					drive-strength = <6>;
					bias-disable;
				};
			};

			qupv3_se9_spi_clk_active: qupv3_se9_spi_clk_active {
				mux {
					pins = "gpio14";
					function = "qup0_se9_l2";
				};

				config {
					pins = "gpio14";
					drive-strength = <6>;
					bias-disable;
				};
			};

			qupv3_se9_spi_cs_active: qupv3_se9_spi_cs_active {
				mux {
					pins = "gpio15";
					function = "qup0_se9_l3";
				};

				config {
					pins = "gpio15";
					drive-strength = <6>;
					bias-disable;
				};
			};

			qupv3_se9_spi_sleep: qupv3_se9_spi_sleep {
				mux {
					pins = "gpio28", "gpio29",
						"gpio14", "gpio15";
					function = "gpio";
				};

				config {
					pins = "gpio28", "gpio29",
						"gpio14", "gpio15";
					drive-strength = <2>;
					bias-disable;
				};
			};
		};

		qupv3_se10_4uart_pins: qupv3_se10_4uart_pins {
			qupv3_se10_default_cts: qupv3_se10_default_cts {
				mux {
					pins = "gpio2";
					function = "gpio";
				};

				config {
					pins = "gpio2";
					drive-strength = <2>;
					bias-disable;
				};
			};

			qupv3_se10_default_rts: qupv3_se10_default_rts {
				mux {
					pins = "gpio3";
					function = "gpio";
				};

				config {
					pins = "gpio3";
					drive-strength = <2>;
					bias-pull-down;
				};
			};

			qupv3_se10_default_tx: qupv3_se10_default_tx {
				mux {
					pins = "gpio21";
					function = "gpio";
				};

				config {
					pins = "gpio21";
					drive-strength = <2>;
					bias-pull-up;
				};
			};

			qupv3_se10_default_rx: qupv3_se10_default_rx {
				mux {
					pins = "gpio20";
					function = "gpio";
				};

				config {
					pins = "gpio20";
					drive-strength = <2>;
					bias-pull-down;
				};
			};

			qupv3_se10_cts: qupv3_se10_cts {
				mux {
					pins = "gpio2";
					function = "qup0_se10_l0";
				};

				config {
					pins = "gpio2";
					drive-strength = <2>;
					bias-disable;
				};
			};

			qupv3_se10_rts: qupv3_se10_rts {
				mux {
					pins = "gpio3";
					function = "qup0_se10_l1";
				};

				config {
					pins = "gpio3";
					drive-strength = <2>;
					bias-pull-down;
				};
			};

			qupv3_se10_tx: qupv3_se10_tx {
				mux {
					pins = "gpio21";
					function = "qup0_se10_l2";
				};

				config {
					pins = "gpio21";
					drive-strength = <2>;
					bias-pull-up;
				};
			};

			qupv3_se10_rx_active: qupv3_se10_rx_active {
				mux {
					pins = "gpio20";
					function = "qup0_se10_l3";
				};

				config {
					pins = "gpio20";
					drive-strength = <2>;
					bias-disable;
				};
			};
		};

		qupv3_se10_i2c_pins: qupv3_se10_i2c_pins {
			qupv3_se10_i2c_sda_active: qupv3_se10_i2c_sda_active {
				mux {
					pins = "gpio2";
					function = "qup0_se10_l0";
				};

				config {
					pins = "gpio2";
					drive-strength = <2>;
					bias-pull-up;
					qcom,i2c_pull;
				};
			};

			qupv3_se10_i2c_scl_active: qupv3_se10_i2c_scl_active {
				mux {
					pins = "gpio3";
					function = "qup0_se10_l1";
				};

				config {
					pins = "gpio3";
					drive-strength = <2>;
					bias-pull-up;
					qcom,i2c_pull;
				};
			};

			qupv3_se10_i2c_sleep: qupv3_se10_i2c_sleep {
				mux {
					pins = "gpio2", "gpio3";
					function = "gpio";
				};

				config {
					pins = "gpio2", "gpio3";
					drive-strength = <2>;
				};
			};
		};

		qupv3_se10_spi_pins: qupv3_se10_spi_pins {
			qupv3_se10_spi_miso_active: qupv3_se10_spi_miso_active {
				mux {
					pins = "gpio2";
					function = "qup0_se10_l0";
				};

				config {
					pins = "gpio2";
					drive-strength = <6>;
					bias-disable;
				};
			};

			qupv3_se10_spi_mosi_active: qupv3_se10_spi_mosi_active {
				mux {
					pins = "gpio3";
					function = "qup0_se10_l1";
				};

				config {
					pins = "gpio3";
					drive-strength = <6>;
					bias-disable;
				};
			};

			qupv3_se10_spi_clk_active: qupv3_se10_spi_clk_active {
				mux {
					pins = "gpio21";
					function = "qup0_se10_l2";
				};

				config {
					pins = "gpio21";
					drive-strength = <6>;
					bias-disable;
				};
			};

			qupv3_se10_spi_cs_active: qupv3_se10_spi_cs_active {
				mux {
					pins = "gpio20";
					function = "qup0_se10_l3";
				};

				config {
					pins = "gpio20";
					drive-strength = <6>;
					bias-disable;
				};
			};

			qupv3_se10_spi_sleep: qupv3_se10_spi_sleep {
				mux {
					pins = "gpio2", "gpio3",
						"gpio21", "gpio20";
					function = "gpio";
				};

				config {
					pins = "gpio2", "gpio3",
						"gpio21", "gpio20";
					drive-strength = <2>;
					bias-disable;
				};
			};
		};

		sdc1_on: sdc1_on {
			clk {
				pins = "sdc1_clk";
				bias-disable;
				drive-strength = <16>;
			};


			cmd {
				pins = "sdc1_cmd";
				bias-pull-up;
				drive-strength = <10>;
			};


			data {
				pins = "sdc1_data";
				bias-pull-up;
				drive-strength = <10>;
			};

			rclk {
				pins = "sdc1_rclk";
				bias-pull-down;
				drive-strength = <2>;
			};
		};

		sdc1_off: sdc1_off {
			clk {
				pins = "sdc1_clk";
				drive-strength = <2>;
				bias-bus-hold;
			};

			cmd {
				pins = "sdc1_cmd";
				drive-strength = <2>;
				bias-bus-hold;
			};

			data {
				pins = "sdc1_data";
				drive-strength = <2>;
				bias-bus-hold;
			};

			rclk {
				pins = "sdc1_rclk";
				drive-strength = <2>;
				bias-bus-hold;
			};
		};

		pmx_sdc3_clk {
			sdc3_clk_on: sdc3_clk_on {
				mux {
					pins = "gpio85";
					function = "sdc2_clk";
				};

				config {
					pins = "gpio85";
					drive-strength = <4>; /* 4 MA */
					bias-disable; /* NO pull */
				};
			};

			sdc3_clk_off: sdc3_clk_off {
				mux {
					pins = "gpio85";
					function = "sdc2_clk";
				};

				config {
					pins = "gpio85";
					bias-disable; /* NO pull */
					drive-strength = <2>; /* 2 MA */
				};
			};
		};

		pmx_sdc3_cmd {
			sdc3_cmd_on: sdc3_cmd_on {
				mux {
					pins = "gpio84";
					function = "sdc2_cmd";
				};

				config {
					pins = "gpio84";
					bias-pull-up; /* pull up */
					drive-strength = <8>; /* 8 MA */
				};
			};

			sdc3_cmd_off: sdc3_cmd_off {
				mux {
					pins = "gpio84";
					function = "sdc2_cmd";
				};

				config {
					pins = "gpio84";
					bias-pull-up; /* pull up */
					drive-strength = <2>; /* 2 MA */
				};
			};
		};

		pmx_sdc3_data {
			sdc3_data_on: sdc3_data_on {
				mux {
					pins = "gpio80","gpio81","gpio82","gpio83";
					function = "sdc2_data";
				};

				config {
					pins = "gpio80","gpio81","gpio82","gpio83";
					bias-pull-up; /* pull up */
					drive-strength = <8>; /* 8 MA */
				};
			};

			sdc3_data_off: sdc3_data_off {
				mux {
					pins = "gpio80","gpio81","gpio82","gpio83";
					function = "sdc2_data";
				};

				config {
					pins = "gpio80","gpio81","gpio82","gpio83";
					bias-pull-up; /* pull up */
					drive-strength = <2>; /* 2 MA */
				};
			};
		};

		pmx_ts_int_active {
			ts_int_active: ts_int_active {
				mux {
					pins = "gpio113";
					function = "gpio";
				};

				config {
					pins = "gpio113";
					drive-strength = <8>;
					bias-pull-up;
					qcom,apps;
				};
			};
		};

		pmx_ts_int_suspend {
			ts_int_suspend: ts_int_suspend {
				mux {
					pins = "gpio113";
					function = "gpio";
				};

				config {
					pins = "gpio113";
					drive-strength = <2>;
					bias-pull-down;
					qcom,remote;
				};
			};
		};

		pmx_ts_reset_active {
			ts_reset_active: ts_reset_active {
				mux {
					pins = "gpio114";
					function = "gpio";
				};

				config {
					pins = "gpio114";
					drive-strength = <8>;
					bias-pull-up;
					qcom,apps;
				};
			};
		};

		pmx_ts_reset_suspend {
			ts_reset_suspend: ts_reset_suspend {
				mux {
					pins = "gpio114";
					function = "gpio";
				};

				config {
					pins = "gpio114";
					drive-strength = <2>;
					bias-pull-down;
					qcom,remote;
				};
			};
		};

		pmx_ts_release {
			ts_release: ts_release {
				mux {
					pins = "gpio113", "gpio114";
					function = "gpio";
				};

				config {
					pins = "gpio113", "gpio114";
					drive-strength = <2>;
					bias-pull-down;
				};
			};
		};
	};
};
